# FIELDS register map
File version: 1.0
Registers are 32-bit, read-write, no defined reset value unless marked. A register's access mark holds for its fields unless they carry their own. Offsets are from the block's base; lines under a group give offsets from that group; [hi:lo] are bit positions; {n}, {i} and the like mark numbered series; 'fields as' and 'values as' point back to an identical list; <NAME> marks a mode.

## Memory map
0x40000000 BITS — Bits in each of SVD's three forms.
0x40001000 MODES — Field modes, written where they differ from the register's.
0x40002000 REPEATED — Fields with dim, and a field derived from another.

## BITS — Bits in each of SVD's three forms.
Base 0x40000000
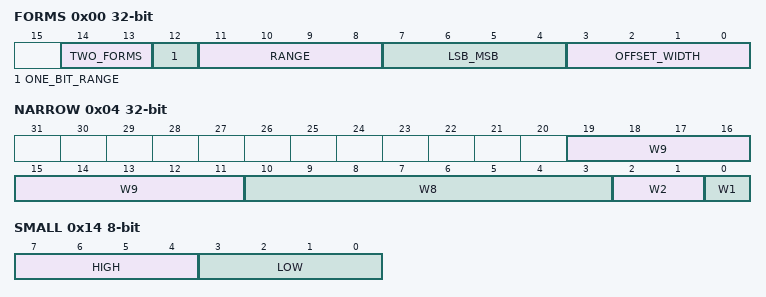
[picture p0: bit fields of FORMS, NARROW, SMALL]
0x00 FORMS — One field per form, and one that states two.
  [14:13] TWO_FORMS — States bitOffset and bitWidth, then lsb and msb: the first form is taken.
  [12] ONE_BIT_RANGE
  [11:8] RANGE — From bitRange.
  [7:4] LSB_MSB — From lsb and msb.
  [3:0] OFFSET_WIDTH — From bitOffset and bitWidth.
0x04 NARROW — A bool, and widths up to 9 bits.
  [19:11] W9, [10:3] W8, [2:1] W2, [0] W1
0x08 W16
  [15:0] V
0x0C W17
  [16:0] V
0x10 W32
  [31:0] V
0x14 SMALL 8-bit — A register of 8 bits has a struct of 8 bits.
  [7:4] HIGH, [3:0] LOW

## MODES — Field modes, written where they differ from the register's.
Base 0x40001000
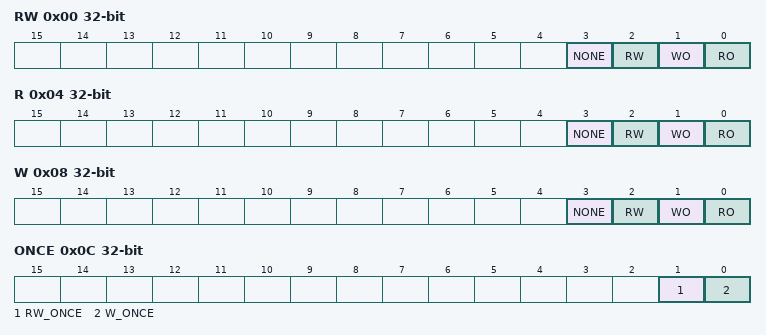
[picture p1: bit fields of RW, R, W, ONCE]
0x00 RW
  [3] NONE, [2] RW, [1] WO wo, [0] RO ro
0x04 R ro
  [3] NONE, [2] RW rw, [1] WO wo, [0] RO
0x08 W wo
  [3] NONE, [2] RW rw, [1] WO, [0] RO ro
0x0C ONCE — Fields writable once: declared without "once", and warned.
  [1] RW_ONCE rw-once — Readable, and writable once.
  [0] W_ONCE write-once — Writable once.
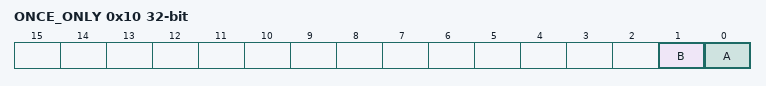
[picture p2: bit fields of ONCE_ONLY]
0x10 ONCE_ONLY access per field — The fields give the register its mode: write-only and writeOnce are both write.
  [1] B wo, [0] A write-once

## REPEATED — Fields with dim, and a field derived from another.
Base 0x40002000
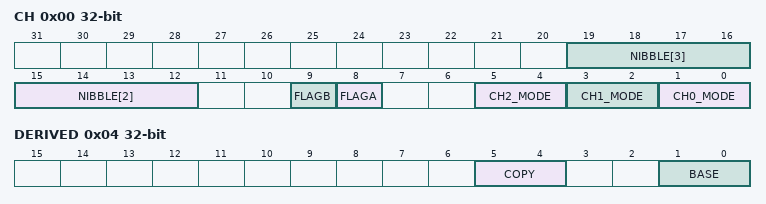
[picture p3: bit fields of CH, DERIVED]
0x00 CH
  [4n+7:4n+4] NIBBLE[{n}] (n=2..3)
  [8] FLAG{x} (x=A,B; step 1) ro
  [2n+1:2n] CH{n}_MODE (n=0..2) — The mode of a channel.
0x04 DERIVED
  [5:4] COPY ro — The field the next one is derived from.
  [1:0] BASE ro — The field the next one is derived from.
